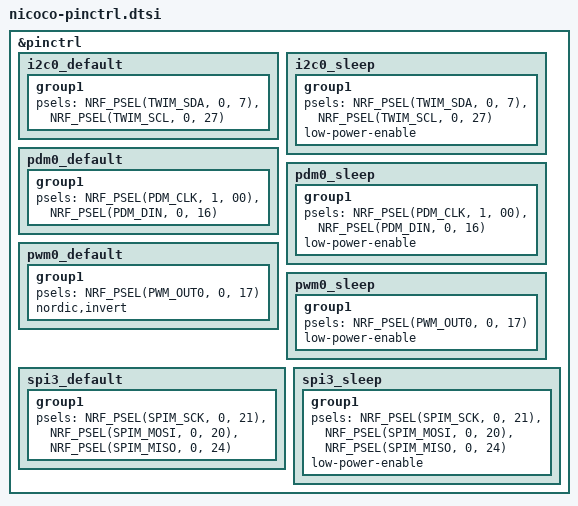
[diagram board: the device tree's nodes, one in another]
&pinctrl {
	i2c0_default: i2c0_default {
		group1 {
			psels = <NRF_PSEL(TWIM_SDA, 0, 7)>,
				<NRF_PSEL(TWIM_SCL, 0, 27)>;
		};
	};

	i2c0_sleep: i2c0_sleep {
		group1 {
			psels = <NRF_PSEL(TWIM_SDA, 0, 7)>,
				<NRF_PSEL(TWIM_SCL, 0, 27)>;
			low-power-enable;
		};
	};

	pdm0_default: pdm0_default {
		group1 {
			psels = <NRF_PSEL(PDM_CLK, 1, 00)>,
				<NRF_PSEL(PDM_DIN, 0, 16)>;
		};
	};

	pdm0_sleep: pdm0_sleep {
		group1 {
			psels = <NRF_PSEL(PDM_CLK, 1, 00)>,
				<NRF_PSEL(PDM_DIN, 0, 16)>;
				low-power-enable;
		};
	};

	pwm0_default: pwm0_default {
		group1 {
			psels = <NRF_PSEL(PWM_OUT0, 0, 17)>;
			nordic,invert;
		};
	};

	pwm0_sleep: pwm0_sleep {
		group1 {
			psels = <NRF_PSEL(PWM_OUT0, 0, 17)>;
			low-power-enable;
		};
	};

	spi3_default: spi3_default {
		group1 {
			psels = <NRF_PSEL(SPIM_SCK, 0, 21)>,
				<NRF_PSEL(SPIM_MOSI, 0, 20)>,
				<NRF_PSEL(SPIM_MISO, 0, 24)>;
		};
	};

	spi3_sleep: spi3_sleep {
		group1 {
			psels = <NRF_PSEL(SPIM_SCK, 0, 21)>,
				<NRF_PSEL(SPIM_MOSI, 0, 20)>,
				<NRF_PSEL(SPIM_MISO, 0, 24)>;
			low-power-enable;
		};
	};
};
